# Template register map
Vendor: VendorName Co.Ltd; Series: SeriesName; File version: 1.2
CPU: CM7 r0p1, little endian, MPU, FPU, 4 interrupt priority bits
Registers are 32-bit, read-write, no defined reset value unless marked. A register's access mark holds for its fields unless they carry their own. Offsets are from the block's base; [hi:lo] are bit positions; {n}, {i} and the like mark numbered series.

## ADCA — Analog-to-Digital Converter A
Base 0x40030000
Same registers: ADCB 0x40031000, ADCC 0x40032000, ADCD 0x40033000
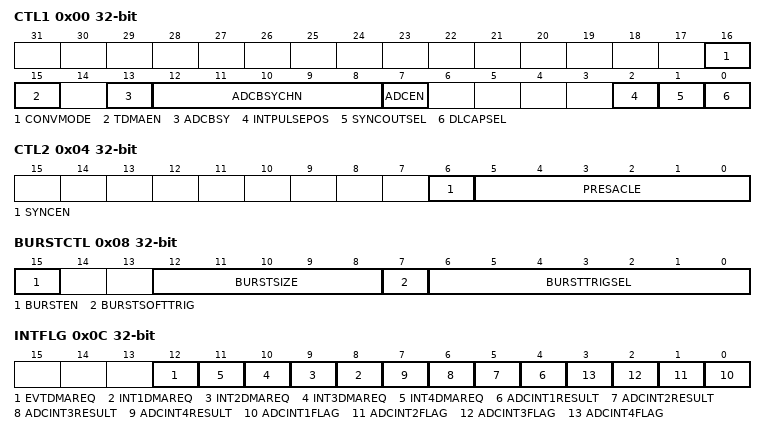
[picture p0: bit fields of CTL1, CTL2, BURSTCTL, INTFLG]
0x00 CTL1 — ADC control register 1
  [16] CONVMODE — ADCA CONVMODE bit: definition of ADC conversion window size
  [15] TDMAEN — ADCA TDMAEN bit: DMA request output control
  [13] ADCBSY ro — ADCA ADCBSY bit: ADC busy flag
  [12:8] ADCBSYCHN ro — ADCA ADCBSYCHN[4:0] bit: ADC busy SOC sequence number
  [7] ADCEN — ADCA ADCEN bit: enable signal for the AD circuit
  [2] INTPULSEPOS — ADCA INTPULSEPOS bit: ADC interrupt output control
  [1] SYNCOUTSEL — ADCA SYNCOUTSEL bit: the control bit for selecting the synchronization source of the ADC controller
  [0] DLCAPSEL — ADCA DLCAPSEL bit: ADC post-processing delay capture unit selection
0x04 CTL2 — ADC control register 2
  [6] SYNCEN — ADCA SYNCEN bit: clock divider circuit synchronization enable function
  [5:0] PRESACLE — ADCA PRESACLE[5:0] bit: ANA ADCCLK clock division coefficient
0x08 BURSTCTL — ADC burst mode control register
  [15] BURSTEN — ADCA BURSTEN bit: enable BURST mode
  [12:8] BURSTSIZE — ADCA BURSTSIZE[4:0] bit: BURST length selection
  [7] BURSTSOFTTRIG wo — ADCA BURSTSOFTTRIG bit: software trigger
  [6:0] BURSTTRIGSEL — ADCA BURSTTRIGSEL[6:0] bit: BURST trigger source selection
0x0C INTFLG ro — ADC interrupt flag register
  [12] EVTDMAREQ — ADCA EVTDMAREQ bit: Flag for DMA request 5
  [n+7] INT{n}DMAREQ (n=1..4) — ADCA INT{n}DMAREQ bit: Flag for DMA request {n}
  [n+3] ADCINT{n}RESULT (n=1..4) — ADCA ADCINT{n}RESULT bit: ADC interrupt {n} result ready flag
  [n-1] ADCINT{n}FLAG (n=1..4) — ADCA ADCINT{n}FLAG bit: the flag for ADC interrupt {n}
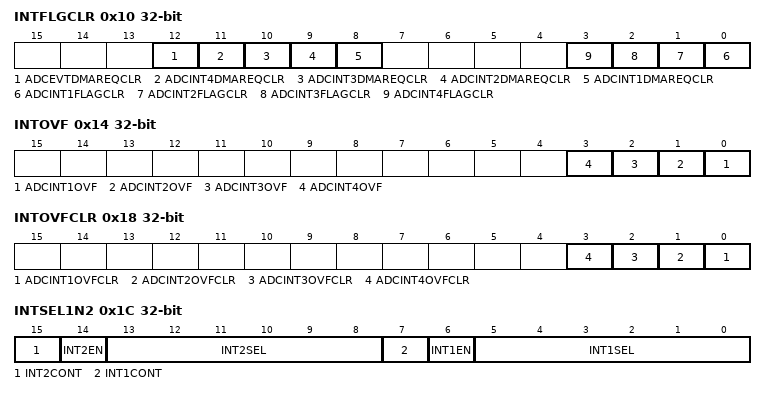
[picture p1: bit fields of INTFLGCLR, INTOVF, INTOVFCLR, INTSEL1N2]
0x10 INTFLGCLR wo — ADC interrupt flag clear register
  [12] ADCEVTDMAREQCLR — ADCA ADCEVTDMAREQCLR bit: ADC generates an event DMA request clear bit
  [11] ADCINT4DMAREQCLR — ADCA ADCINT4DMAREQCLR bit: the source of the ADC generation is the DMA request clear bit of interrupt 4
  [10] ADCINT3DMAREQCLR — ADCA ADCINT3DMAREQCLR bit: the source of the ADC generation is the DMA request clear bit of interrupt 3
  [9] ADCINT2DMAREQCLR — ADCA ADCINT2DMAREQCLR bit: the source of the ADC generation is the DMA request clear bit of interrupt 1
  [8] ADCINT1DMAREQCLR — ADCA ADCINT1DMAREQCLR bit: the source of the ADC generation is the DMA request clear bit of interrupt 2
  [n-1] ADCINT{n}FLAGCLR (n=1..4) — ADCA ADCINT{n}FLAGCLR bit: clear the ADC interrupt {n} flag
0x14 INTOVF ro — ADC interrupt overflow flag register
  [n-1] ADCINT{n}OVF (n=1..4) — ADCA ADCINT{n}OVF bit: overflow flag of interrupt {n}
0x18 INTOVFCLR wo — ADC interrupt overflow flag clear register
  [n-1] ADCINT{n}OVFCLR (n=1..4) — ADCA ADCINT{n}OVFCLR bit: interrupt {n} overflow flag clear bit
0x1C INTSEL1N2 — ADC interrupt 1 and 2 configuration register
  [15] INT2CONT — ADCA INT2CONT bit: enable of the continuous interruption mode of interruption 2
  [14] INT2EN — ADCA INT2EN bit: enable the interrupt 2 flag
  [13:8] INT2SEL — ADCA INT2SEL[5:0] bit: interrupt 2's interruption source selection
  [7] INT1CONT — ADCA INT1CONT bit: enable of the continuous interruption mode of interruption 1
  [6] INT1EN — ADCA INT1EN bit: enable the interrupt 1 flag
  [5:0] INT1SEL — ADCA INT1SEL[5:0] bit: interrupt 1's interruption source selection
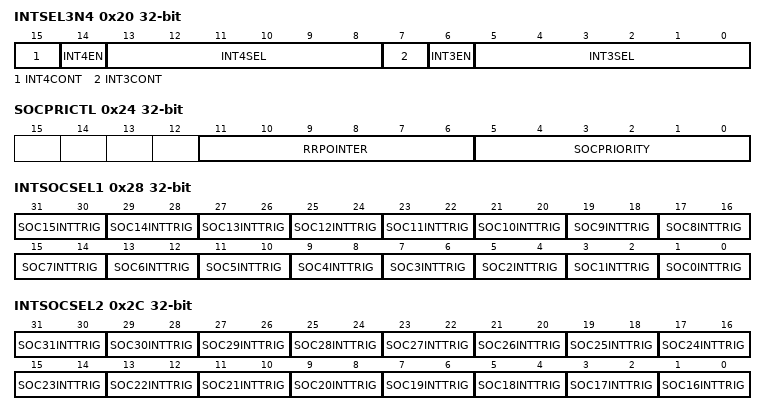
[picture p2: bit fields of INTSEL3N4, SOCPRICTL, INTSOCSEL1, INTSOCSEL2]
0x20 INTSEL3N4 — ADC interrupt 3 and 4 configuration register
  [15] INT4CONT — ADCA INT4CONT bit: enable of the continuous interruption mode of interruption 4
  [14] INT4EN — ADCA INT4EN bit: enable the interrupt 4 flag
  [13:8] INT4SEL — ADCA INT4SEL[5:0] bit: interrupt 4's interruption source selection
  [7] INT3CONT — ADCA INT3CONT bit: enable of the continuous interruption mode of interruption 3
  [6] INT3EN — ADCA INT3EN bit: enable the interrupt 3 flag
  [5:0] INT3SEL — ADCA INT3SEL[5:0] bit: interrupt 3's interruption source selection
0x24 SOCPRICTL — ADC SOC priority configuration register
  [11:6] RRPOINTER ro — ADCA RRPOINTER[5:0] bit: round robin pointer
  [5:0] SOCPRIORITY — ADCA SOCPRIORITY[5:0] bit: SOC priority register
0x28 INTSOCSEL1 — ADC interrupt trig SOC select register 1
  [2n+1:2n] SOC{n}INTTRIG (n=0..15) — ADCA SOC{n}INTTRIG[1:0] bit: SOC{n} interrupt trigger source selection
0x2C INTSOCSEL2 — ADC interrupt trig SOC select register 2
  [2n-31:2n-32] SOC{n}INTTRIG (n=16..31) — ADCA SOC{n}INTTRIG[1:0] bit: SOC{n} interrupt trigger source selection
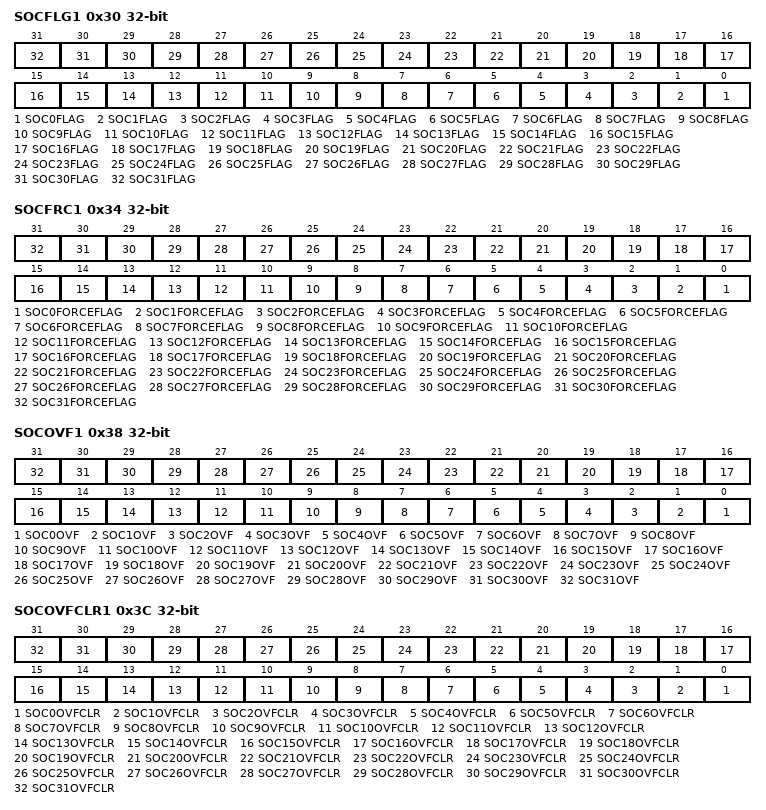
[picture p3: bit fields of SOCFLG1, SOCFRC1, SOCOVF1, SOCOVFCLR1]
0x30 SOCFLG1 ro — ADC SOC pending flag register 1
  [n] SOC{n}FLAG (n=0..31) — ADCA SOC{n}FLAG bit: SOC{n} is pended flag
0x34 SOCFRC1 wo — ADC SOC force register 1
  [n] SOC{n}FORCEFLAG (n=0..31) — ADCA SOC{n}FORCEFLAG bit: force the start of the conversion of SOC{n}
0x38 SOCOVF1 ro — ADC SOC pending flag overflow register 1
  [n] SOC{n}OVF (n=0..31) — ADCA SOC{n}OVF bit: SOC{n} triggers the overflow flag
0x3C SOCOVFCLR1 wo — ADC SOC pending flag overflow clear register 1
  [n] SOC{n}OVFCLR (n=0..31) — ADCA SOC{n}OVFCLR bit: SOC{n} triggers the clearing of the overflow flag
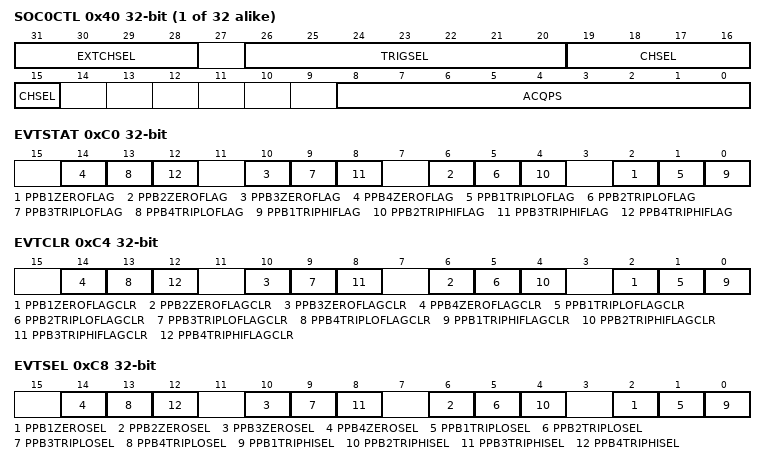
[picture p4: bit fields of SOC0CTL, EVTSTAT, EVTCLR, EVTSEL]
{0x40+4i} SOC{i}CTL (i=0..31) — ADC SOC{i} control register
  [31:28] EXTCHSEL — ADCA EXTCHSEL[3:0] bit: external channel mux selection
  [26:20] TRIGSEL — ADCA TRIGSEL[6:0] bit: selection of the trigger source for SOC{i}
  [19:15] CHSEL — ADCA CHSEL[4:0] bit: SOC{i} conversion channel selection
  [8:0] ACQPS — ADCA ACQPS[8:0] bit: SOC{i} sample window time configuration
0xC0 EVTSTAT ro — ADC event status register
  [4n-2] PPB{n}ZEROFLAG (n=1..4) — ADCA PPB{n}ZEROFLAG bit: PPB{n} zero-crossing flag
  [4n-3] PPB{n}TRIPLOFLAG (n=1..4) — ADCA PPB{n}TRIPLOFLAG bit: PPB{n} has passed the lower limit flag
  [4n-4] PPB{n}TRIPHIFLAG (n=1..4) — ADCA PPB{n}TRIPHIFLAG bit: PPB{n} exceeds the higher limit flag
0xC4 EVTCLR — ADC event clear register
  [4n-2] PPB{n}ZEROFLAGCLR (n=1..4) — ADCA PPB{n}ZEROFLAGCLR bit: PPB{n} zero-crossing flag clearing signal
  [4n-3] PPB{n}TRIPLOFLAGCLR (n=1..4) — ADCA PPB{n}TRIPLOFLAGCLR bit: PPB{n} has passed the lower limit flag clearing signal
  [4n-4] PPB{n}TRIPHIFLAGCLR (n=1..4) — ADCA PPB{n}TRIPHIFLAGCLR bit: PPB{n} higher limit flag clearing signal
0xC8 EVTSEL — ADC event selection register
  [4n-2] PPB{n}ZEROSEL (n=1..4) — ADCA PPB{n}ZEROSEL bit: PPB{n} zero-crossing event enable
  [4n-3] PPB{n}TRIPLOSEL (n=1..4) — ADCA PPB{n}TRIPLOSEL bit: PPB{n} enable the lower limit event trigger
  [4n-4] PPB{n}TRIPHISEL (n=1..4) — ADCA PPB{n}TRIPHISEL bit: PPB{n} over higher limit event enable
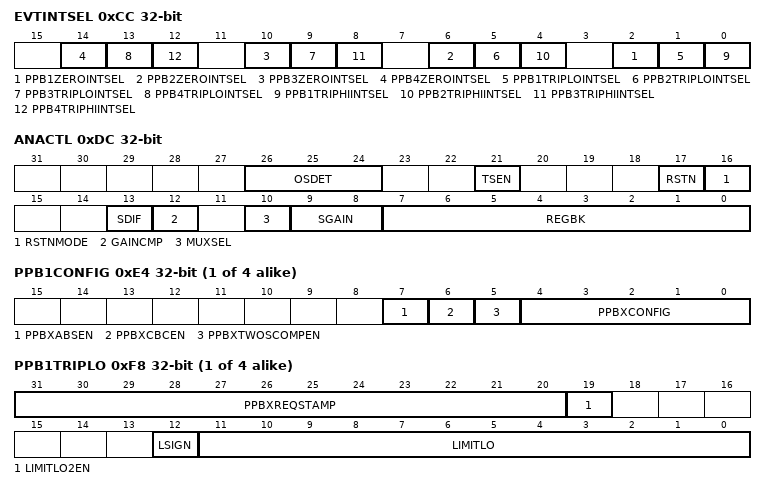
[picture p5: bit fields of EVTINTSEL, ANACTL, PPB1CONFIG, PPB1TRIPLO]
0xCC EVTINTSEL — ADC event interrupt selection register
  [4n-2] PPB{n}ZEROINTSEL (n=1..4) — ADCA PPB{n}ZEROINTSEL bit: PPB{n} zero-crossing event interruption enable
  [4n-3] PPB{n}TRIPLOINTSEL (n=1..4) — ADCA PPB{n}TRIPLOINTSEL bit: PPB{n} enable interruption reaching the lower limit event
  [4n-4] PPB{n}TRIPHIINTSEL (n=1..4) — ADCA PPB{n}TRIPHIINTSEL bit: PPB{n} over higher limit event interruption enable
0xD4 TRIMPN — ADC trim register
  [13:8] OFFSET — ADCA OFFSET[5:0] bit: OFFSET set value
0xD8 COUNTER ro — ADC counter register
  [11:0] FREECOUNT — ADCA FREECOUNT[11:0] bit: FREECOUNT count value
0xDC ANACTL — ADC analog control register
  [26:24] OSDET — ADCA OSDET[2:0] bit: open-closed detection TRIM value
  [21] TSEN — ADCA TSEN bit: temperature sensor enable
  [17] RSTN — ADCA RSTN bit: software-controlled analog AD reset signal
  [16] RSTNMODE — ADCA RSTNMODE bit: reset signal mode of ADC
  [13] SDIF — ADCA SDIF bit: Analog channel input selection
  [12] GAINCMP — ADCA GAINCMP bit: internal delay time selection
  [10] MUXSEL — ADCA MUXSEL bit: sample input selection
  [9:8] SGAIN — ADCA SGAIN[1:0] bit: channel input voltage gain selection
  [7:0] REGBK — ADCA REGBK[7:0] bit: backup debugging port
0xE0 ANATRIM — ADC analog trim register
  [0] DISH — ADCA DISH bit: work mode selection signal
{0xCC+0x18*i} PPB{i}CONFIG (i=1..4) — ADC PPB{i} configuration register
  [7] PPBXABSEN — ADCA PPBXABSEN bit: enable of the absolute value of the PPB{i}
  [6] PPBXCBCEN — ADCA PPBXCBCEN bit: enable for self-clearing of the marking of PPB{i}
  [5] PPBXTWOSCOMPEN — ADCA PPBXTWOSCOMPEN bit: error in the calculation of polarity selection for PPB{i}
  [4:0] PPBXCONFIG — ADCA PPBXCONFIG[4:0] bit: PPB{i} configuration register
{0xD0+0x18*i} PPB{i}STAMP ro (i=1..4) — ADC PPB{i} delay stamp register
  [11:0] PPBXDLYSTAMP — ADCA PPBXDLYSTAMP[11:0] bit: the duration of delay captured by PPB{i}
{0xD4+0x18*i} PPB{i}OFFCAL (i=1..4) — ADC PPB{i} offset calibration register
  [9:0] PPBXOFFCAL — ADCA PPBXOFFCAL[9:0] bit: the calculation coefficients of the error calibration function for the ADC PPB{i}
{0xD8+0x18*i} PPB{i}OFFREF (i=1..4) — ADC PPB{i} offset reference register
  [11:0] PPBXOFFREF — ADCA PPBXOFFREF[11:0] bit: the calculation coefficients of the error calculation function for the ADC PPB{i}
{0xDC+0x18*i} PPB{i}TRIPHI (i=1..4) — ADC PPB{i} high limit register
  [23:0] LIMITHI — ADCA LIMITHI[23:0] bit: the higher limit value of the PPB{i}
{0xE0+0x18*i} PPB{i}TRIPLO (i=1..4) — ADC PPB{i} low limit and trig-time register
  [31:20] PPBXREQSTAMP ro — ADCA PPBXREQSTAMP[11:0] bit: PPB{i} request timestamp
  [19] LIMITLO2EN — ADCA LIMITLO2EN bit: extend the enable of the lower limit register 2
  [12] LSIGN — ADCA LSIGN bit: the sign bit of the lower limit register
  [11:0] LIMITLO — ADCA LIMITLO[11:0] bit: the lower limit value of the PPB{i}
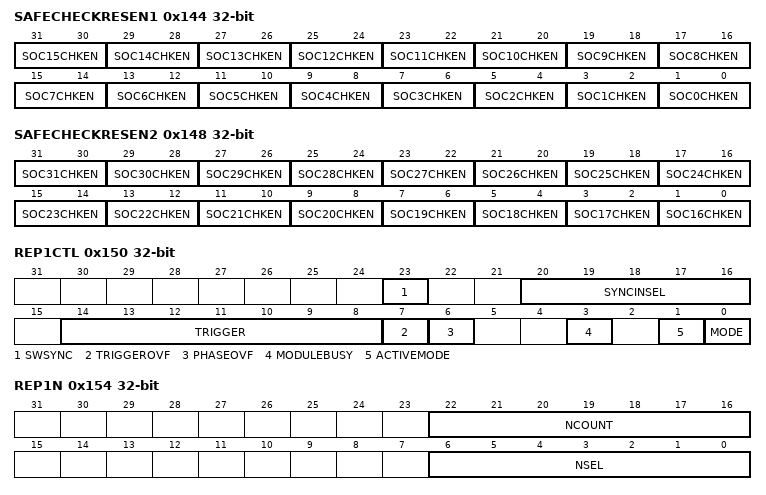
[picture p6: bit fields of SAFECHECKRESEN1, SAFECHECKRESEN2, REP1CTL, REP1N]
0x144 SAFECHECKRESEN1 — ADC result safe check enable register 1
  [2n+1:2n] SOC{n}CHKEN (n=0..15) — ADCA SOC{n}CHKEN[1:0] bit: determine which result will be transmitted to the result safety checker SOC{n}
0x148 SAFECHECKRESEN2 — ADC result safe check enable register 2
  [2n-31:2n-32] SOC{n}CHKEN (n=16..31) — ADCA SOC{n}CHKEN[1:0] bit: determine which result will be transmitted to the result safety checker SOC{n}
0x14C INTCYCLE — ADC interrupt delay cycle register
  [15:0] ADCINTCYCLEDELAY — ADCA ADCINTCYCLEDELAY[15:0] bit: the delay time for the ADC's premature interruption
0x150 REP1CTL — ADC repeater1 control register
  [23] SWSYNC wo — ADCA SWSYNC bit: software synchronization bit of trigger source repeater 1
  [20:16] SYNCINSEL — ADCA SYNCINSEL[4:0] bit: trigger repeater 1 synchronous input selection
  [14:8] TRIGGER — ADCA TRIGGER[6:0] bit: ADC trigger repeater 1-source selection triggered
  [7] TRIGGEROVF — ADCA TRIGGEROVF bit: ADC trigger repeater 1 over-sampling triggers overflow
  [6] PHASEOVF — ADCA PHASEOVF bit: ADC trigger repeater 1 phase delay overflow
  [3] MODULEBUSY ro — ADCA MODULEBUSY bit: ADC trigger repeater 1 busy indicator bit
  [1] ACTIVEMODE ro — ADCA ACTIVEMODE bit: decide whether to repeat the repeater or filter the trigger source
  [0] MODE — ADCA MODE bit: ADC trigger repeater 1 mode selection
0x154 REP1N — ADC repeater1 count setting register
  [22:16] NCOUNT ro — ADCA NCOUNT[6:0] bit: ADC trigger repeater 1 trigger count
  [6:0] NSEL — ADCA NSEL[6:0] bit: ADC trigger repeater 1 trigger count selection
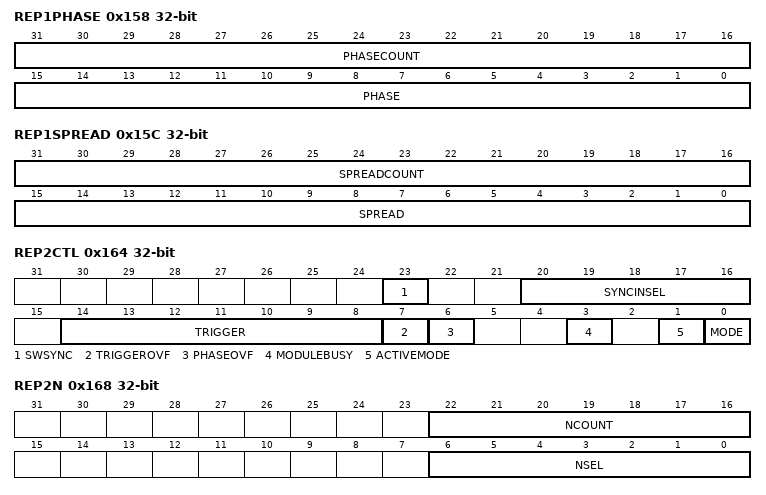
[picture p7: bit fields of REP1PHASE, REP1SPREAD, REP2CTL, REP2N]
0x158 REP1PHASE — ADC repeater1 phase control register
  [31:16] PHASECOUNT ro — ADCA PHASECOUNT[15:0] bit: ADC trigger repeater 1 phase delay state
  [15:0] PHASE — ADCA PHASE[15:0] bit: ADC trigger repeater 1 phase delay configuration
0x15C REP1SPREAD — ADC repeater1 spread register
  [31:16] SPREADCOUNT ro — ADCA SPREADCOUNT[15:0] bit: ADC triggers repeater 1 trigger gap state
  [15:0] SPREAD — ADCA SPREAD[15:0] bit: ADC triggers repeater 1 trigger gap delay configuration
0x160 REP1FRC wo — ADC repeater1 force register
  [0] SWFRC — ADCA SWFRC bit: force the trigger source input of the trigger repeater 1
0x164 REP2CTL — ADC repeater2 control register
  [23] SWSYNC wo — ADCA SWSYNC bit: software synchronization bit of trigger source repeater 2
  [20:16] SYNCINSEL — ADCA SYNCINSEL[4:0] bit: trigger repeater 2 synchronous input selection
  [14:8] TRIGGER — ADCA TRIGGER[6:0] bit: ADC trigger repeater 2-source selection triggered
  [7] TRIGGEROVF — ADCA TRIGGEROVF bit: ADC trigger repeater 2 over-sampling triggers overflow
  [6] PHASEOVF — ADCA PHASEOVF bit: ADC trigger repeater 2 phase delay overflow
  [3] MODULEBUSY ro — ADCA MODULEBUSY bit: ADC trigger repeater 2 busy indicator bit
  [1] ACTIVEMODE ro — ADCA ACTIVEMODE bit: decide whether to repeat the repeater or filter the trigger source
  [0] MODE — ADCA MODE bit: ADC trigger repeater 2 mode selection
0x168 REP2N — ADC repeater2 count setting register
  [22:16] NCOUNT ro — ADCA NCOUNT[6:0] bit: ADC trigger repeater 2 trigger count
  [6:0] NSEL — ADCA NSEL[6:0] bit: ADC trigger repeater 2 trigger count selection
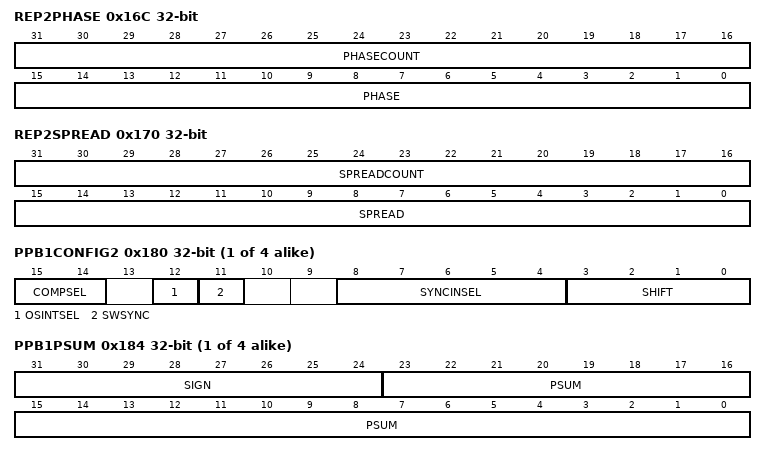
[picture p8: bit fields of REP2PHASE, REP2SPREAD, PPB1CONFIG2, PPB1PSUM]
0x16C REP2PHASE — ADC repeater2 phase control register
  [31:16] PHASECOUNT ro — ADCA PHASECOUNT[15:0] bit: ADC trigger repeater 2 phase delay state
  [15:0] PHASE — ADCA PHASE[15:0] bit: ADC trigger repeater 2 phase delay configuration
0x170 REP2SPREAD — ADC repeater2 spread register
  [31:16] SPREADCOUNT ro — ADCA SPREADCOUNT[15:0] bit: ADC triggers repeater 2 trigger gap state
  [15:0] SPREAD — ADCA SPREAD[15:0] bit: ADC triggers repeater 2 trigger gap delay configuration
0x174 REP2FRC wo — ADC repeater2 force register
  [0] SWFRC — ADCA SWFRC bit: force the trigger source input of the trigger repeater 2
{0x154+0x24*i} PPB{i}LIMIT (i=1..4) — ADC PPB{i} limit register
  [9:0] LIMIT — ADCA LIMIT[9:0] bit: PPB{i}'s post-processing limit
{0x158+0x24*i} PPB{i}PCOUNT ro (i=1..4) — ADC PPB{i} temporary count register
  [9:0] PCOUNT — ADCA PCOUNT[9:0] bit: PPB{i}'s post-processing count buffer
{0x15C+0x24*i} PPB{i}CONFIG2 (i=1..4) — ADC PPB{i} configuration register 2
  [15:14] COMPSEL — ADCA COMPSEL[1:0] bit: PPB{i} compare source selection
  [12] OSINTSEL — ADCA OSINTSEL bit: PPB{i} interrupt source selection
  [11] SWSYNC wo — ADCA SWSYNC bit: PPB{i} software force synchronization
  [8:4] SYNCINSEL — ADCA SYNCINSEL[4:0] bit: PPB{i} synchronous input selection bit
  [3:0] SHIFT — ADCA SHIFT[3:0] bit: PPB{i} compares source selections
{0x160+0x24*i} PPB{i}PSUM ro (i=1..4) — ADC PPB{i} temporary sum register
  [31:24] SIGN — ADCA SIGN[7:0] bit: sign extension bit
  [23:0] PSUM — ADCA PSUM[23:0] bit: the sum result of PPB{i}'s post-processing count buffer
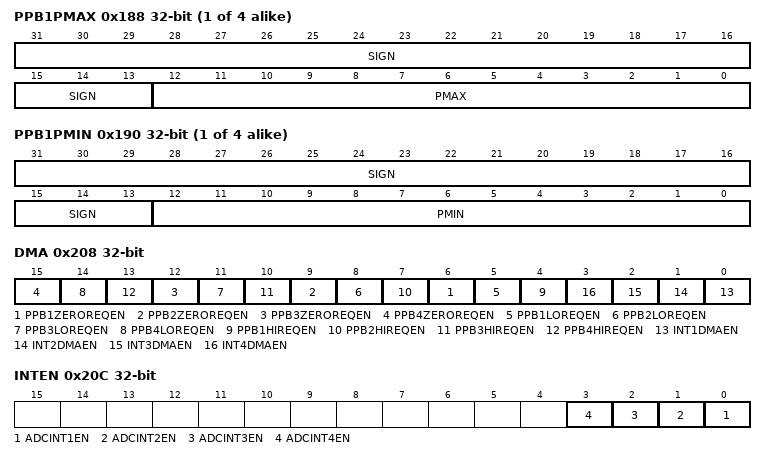
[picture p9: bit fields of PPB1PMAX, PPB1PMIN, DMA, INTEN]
{0x164+0x24*i} PPB{i}PMAX ro (i=1..4) — ADC PPB{i} temporary max register
  [31:13] SIGN — ADCA SIGN[18:0] bit: sign extension bit
  [12:0] PMAX — ADCA PMAX[12:0] bit: the maximum value of PPB{i}'s post-processing count buffer
{0x168+0x24*i} PPB{i}PMAXI ro (i=1..4) — ADC PPB{i} temporary max index register
  [9:0] PMAXI — ADCA PMAXI[9:0] bit: PPB{i} stores the maximum index value for post-processing
{0x16C+0x24*i} PPB{i}PMIN ro (i=1..4) — ADC PPB{i} temporary min register
  [31:13] SIGN — ADCA SIGN[18:0] bit: sign extension bit
  [12:0] PMIN — ADCA PMIN[12:0] bit: the minimum value of PPB{i}'s post-processing count buffer
{0x170+0x24*i} PPB{i}PMINI ro (i=1..4) — ADC PPB{i} temporary min index register
  [9:0] PMINI — ADCA PMINI[9:0] bit: PPB{i} store the minimum index value for post-processing
{0x174+0x24*i} PPB{i}TRIPLO2 (i=1..4) — ADC PPB{i} low limit register 2
  [23:0] LIMITLO — ADCA LIMITLO[23:0] bit: PPB{i}'s lower limit value
0x208 DMA — ADC DMA enable register
  [3n+3] PPB{n}ZEROREQEN (n=1..4) — ADCA PPB{n}ZEROREQEN bit: PPB{n}'s zero-crossing DMA request enable
  [3n+2] PPB{n}LOREQEN (n=1..4) — ADCA PPB{n}LOREQEN bit: PPB{n}'s belowing lower limit DMA request enable
  [3n+1] PPB{n}HIREQEN (n=1..4) — ADCA PPB{n}HIREQEN bit: PPB{n}'s overing higher limit DMA request enable
  [n-1] INT{n}DMAEN (n=1..4) — ADCA INT{n}DMAEN bit: enable of DMA request interruption {n}
0x20C INTEN — ADC interrupt enable register
  [n-1] ADCINT{n}EN (n=1..4) — ADCA ADCINT{n}EN bit: output enable for ADC interrupt {n}
